# 3061MNNIC8 register map
File version: 1.0
Registers are 32-bit, access per field, reset 0x0 unless marked. A register's access mark holds for its fields unless they carry their own. Offsets are from the block's base; lines under a group give offsets from that group; [hi:lo] are bit positions; {n}, {i} and the like mark numbered series; 'fields as' and 'values as' point back to an identical list; <NAME> marks a mode.

## Memory map
0x10000000 CRG size 0xF14 — CRG peripheral interface
0x10010000 CMM size 0x30 — CMM peripheral interface
0x10100000 SYSCTRL0 size 0xE88 — SYSCTRL0_REG peripheral interface
0x10100000 SYSCTRL1 size 0x9008 — SYSCTRL1_REG peripheral interface
0x14000000 UART0 size 0x64 — UART peripheral interface
0x14001000 UART1 size 0x64
0x14002000 UART2 size 0x64
0x14003000 UART3 size 0x64
0x14100000 I2C0 size 0x200 — I2C peripheral interface
0x14101000 I2C1 size 0x200
0x14200000 SPI0 size 0x34 — SPI peripheral interface
0x14201000 SPI1 size 0x34
0x14300000 TIMER0 size 0x24 — TIMER peripheral interface
0x14301000 TIMER1 size 0x24
0x14302000 TIMER2 size 0x24
0x14303000 TIMER3 size 0x24
0x14380000 MTIMER size 0x1C — MTIMER peripheral interface
0x14400000 WWDG size 0x20 — WWDG peripheral interface
0x14401000 IWDG size 0x20 — IWDG peripheral interface
0x14500000 GPIO0 size 0x420 — GPIO peripheral interface
0x14501000 GPIO1 size 0x420
0x14502000 GPIO2 size 0x420
0x14503000 GPIO3 size 0x420
0x14504000 GPIO4 size 0x420
0x14505000 GPIO5 size 0x420
0x14600000 CAN size 0x16C — CAN peripheral interface
0x14700000 GPT0 size 0x50C — GPT peripheral interface
0x14701000 GPT1 size 0x50C
0x14702000 GPT2 size 0x50C
0x14703000 GPT3 size 0x50C
0x14710000 EFC size 0x608 — HIEFC_COMMON_REGS peripheral interface
0x14720000 FLASH_RGN0_SHADOWS size 0x24 — FLASH_RGN0_SHADOWS peripheral interface
0x14720000 FLASH_RGN1_SHADOWS size 0x1024 — FLASH_RGN1_SHADOWS peripheral interface
0x147E0000 PMC size 0xF14 — PMC peripheral interface
0x147F0000 IOCMG_AON size 0x20 — IOCMG_AON peripheral interface
0x147F0000 IOCMG_CORE size 0x1A8 — IOCMG_CORE peripheral interface
0x14800000 CRC size 0x21 — CRC peripheral interface
0x14A00000 APT0 size 0x734 — APT peripheral interface
0x14A01000 APT1 size 0x734
0x14A02000 APT2 size 0x734
0x14A03000 APT3 size 0x734
0x14B00000 CAPM0 size 0x50 — CAPM peripheral interface
0x14B01000 CAPM1 size 0x50
0x14B02000 CAPM2 size 0x50
0x14B03000 CAPM_COMM size 0x38 — CAPM_COMM peripheral interface
0x14C00000 QDM0 size 0x6C — QDM peripheral interface
0x14C01000 QDM1 size 0x6C
0x18000000 ADC size 0x844 — ADC peripheral interface
0x18100000 VREF size 0x4C — VREF peripheral interface
0x18200000 PGA0 size 0x68 — PGA peripheral interface
0x18201000 PGA1 size 0x68
0x18300000 ACMP size 0x94 — ACMP peripheral interface
0x18400000 DAC size 0x14 — DAC peripheral interface
0x18500000 TSENSOR size 0x14 — TSENSOR peripheral interface
0x1C000000 DMA size 0x214 — DMA peripheral interface

## Interrupts
2 DAC
2 TSENSOR
4 PGA (PGA0)
4 VREF
5 FLASH_RGN0_SHADOWS
5 IOCMG_AON
6 FLASH_RGN1_SHADOWS
6 MTIMER
8 CAPM_COMM
8 IWDG
8 PMC
8 WWDG
9 CRC
9 GPIO (GPIO0)
9 TIMER (TIMER0)
10 SYSCTRL1_REG (SYSCTRL1)
11 ACMP
12 CMM
13 SPI (SPI0)
14 SYSCTRL0_REG (SYSCTRL0)
16 GPT (GPT0)
17 UART (UART0)
19 CAPM (CAPM0)
22 I2C (I2C0)
27 QDM (QDM0)
28 HIEFC_COMMON_REGS (EFC)
37 CAN
40 DMA
41 IOCMG_CORE
61 APT (APT0)
61 CRG
104 ADC

## ACMP — ACMP peripheral interface
Base 0x18300000
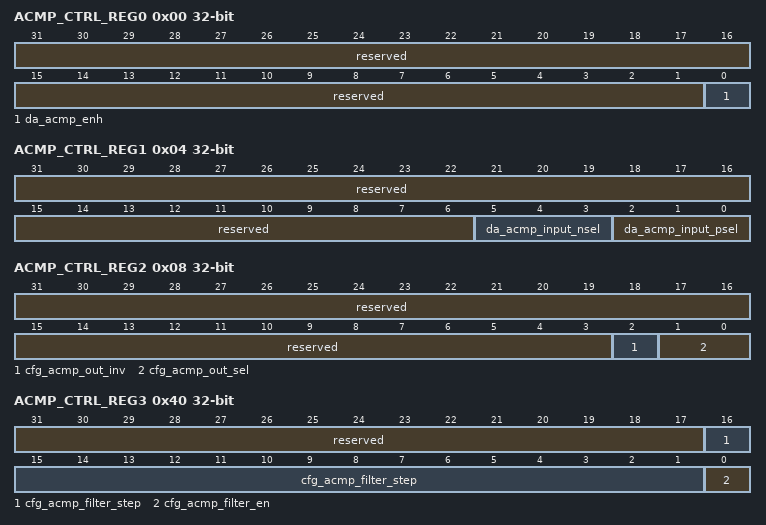
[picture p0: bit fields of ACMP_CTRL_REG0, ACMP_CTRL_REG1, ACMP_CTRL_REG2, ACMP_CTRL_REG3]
0x00 ACMP_CTRL_REG0 — ACMP控制寄存器0。
  [31:1] reserved ro — 保留。
  [0] da_acmp_enh rw — 比较器使能信号： 0:关闭； 1:使能。
0x04 ACMP_CTRL_REG1 — ACMP控制寄存器1。
  [31:6] reserved ro — 保留。
  [5:3] da_acmp_input_nsel rw — 比较器输入通道N端选通； 000：VINN0； 001：VINN1； 010：VINN2； 011：VINN3； 100：VINN4； 101：VINN5； 其他：未使用。
  [2:0] da_acmp_input_psel rw — 比较器输入通道P端选通； 000：VINP0； 001：VINP1； 010：VINP2； 011：VINP3； 100：VINP4； 101：VINP5； 其他：未使用。
0x08 ACMP_CTRL_REG2 — ACMP控制寄存器2。
  [31:3] reserved ro — 保留。
  [2] cfg_acmp_out_inv rw — 比较器结果极性选择： 0：结果不取反； 1：结果取反。
  [1:0] cfg_acmp_out_sel rw — 比较器输出结果选择： 00：原始比较结果； 01：滤波后结果； 10：屏蔽后结果； 11：保留。
0x40 ACMP_CTRL_REG3 — ACMP滤波控制寄存器。
  [31:17] reserved ro — 保留。
  [16:1] cfg_acmp_filter_step rw — 比较器滤波步长。
  [0] cfg_acmp_filter_en rw — 比较器滤波使能： 0:关闭; 1:使能。
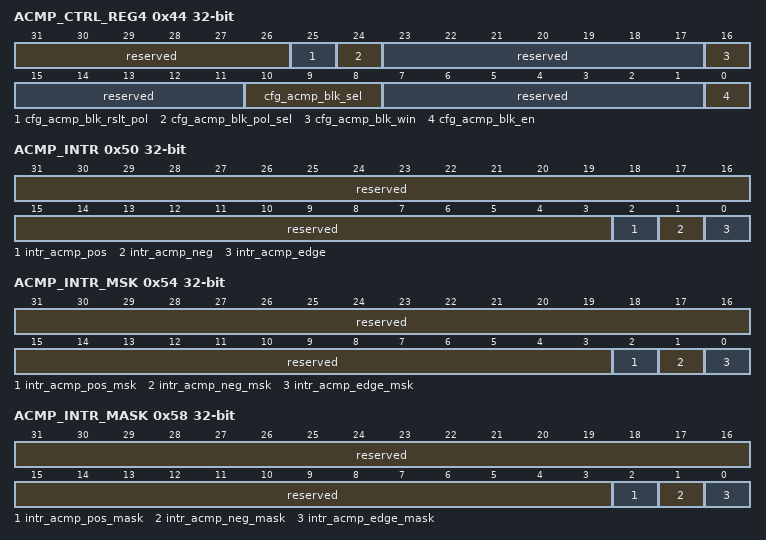
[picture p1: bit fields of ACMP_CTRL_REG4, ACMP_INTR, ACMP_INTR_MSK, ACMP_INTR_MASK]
0x44 ACMP_CTRL_REG4 — ACMP屏蔽控制寄存器。
  [31:26] reserved ro — 保留。
  [25] cfg_acmp_blk_rslt_pol rw — 屏蔽结果极性选择： 0：屏蔽结果为低电平； 1：屏蔽结果为高电平。
  [24] cfg_acmp_blk_pol_sel rw — 屏蔽窗口极性选择： 0：高电平屏蔽窗有效； 1：低电平屏蔽窗有效；
  [23:17] reserved ro — 保留。
  [16] cfg_acmp_blk_win rw — 软件配置屏蔽窗口；
  [15:11] reserved ro — 保留。
  [10:8] cfg_acmp_blk_sel rw — 比较器屏蔽窗口选择： 000：软件配置屏蔽窗口； 001：APT0输出屏蔽窗口； 010：APT1输出屏蔽窗口； 011：APT2输出屏蔽窗口； 100：APT3输出屏蔽窗口； 其他：保留。
  [7:1] reserved ro — 保留。
  [0] cfg_acmp_blk_en rw — 比较器屏蔽使能： 0:关闭; 1:使能。
0x50 ACMP_INTR — ACMP中断原始状态寄存器。
  [31:3] reserved ro — 保留。
  [2] intr_acmp_pos rw — 比较结果上升沿中断状态。
  [1] intr_acmp_neg rw — 比较结果下降沿中断状态。
  [0] intr_acmp_edge rw — 比较结果翻转沿中断状态。
0x54 ACMP_INTR_MSK ro — ACMP中断屏蔽后状态寄存器。
  [31:3] reserved — 保留。
  [2] intr_acmp_pos_msk — 比较结果上升沿屏蔽后中断状态。
  [1] intr_acmp_neg_msk — 比较结果下降沿屏蔽后中断状态。
  [0] intr_acmp_edge_msk — 比较结果翻转沿屏蔽后中断状态。
0x58 ACMP_INTR_MASK — ACMP中断屏蔽寄存器。
  [31:3] reserved ro — 保留。
  [2] intr_acmp_pos_mask rw — 比较结果上升沿中断屏蔽寄存器： 0：屏蔽中断； 1：不屏蔽。
  [1] intr_acmp_neg_mask rw — 比较结果下降沿中断屏蔽寄存器： 0：屏蔽中断； 1：不屏蔽。
  [0] intr_acmp_edge_mask rw — 比较结果翻转沿中断屏蔽寄存器： 0：屏蔽中断； 1：不屏蔽。
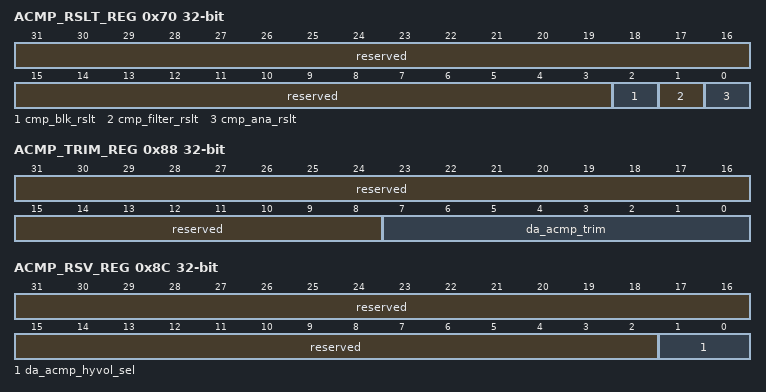
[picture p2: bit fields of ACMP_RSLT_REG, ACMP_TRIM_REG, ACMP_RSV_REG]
0x70 ACMP_RSLT_REG ro — ACMP结果寄存器。
  [31:3] reserved — 保留。
  [2] cmp_blk_rslt — 比较器屏蔽后结果。
  [1] cmp_filter_rslt — 比较器滤波后结果。
  [0] cmp_ana_rslt — 比较器原始比较结果。
0x88 ACMP_TRIM_REG — ACMP TRIM寄存器。
  [31:8] reserved ro — 保留。
  [7:0] da_acmp_trim rw — ACMP TIRM寄存器。
0x8C ACMP_RSV_REG — ACMP预留寄存器。
  [31:2] reserved ro — 保留。
  [1:0] da_acmp_hyvol_sel rw — 迟滞电压选择： 00：0mV； 01：10mV； 10：20mV； 11：30mV。
